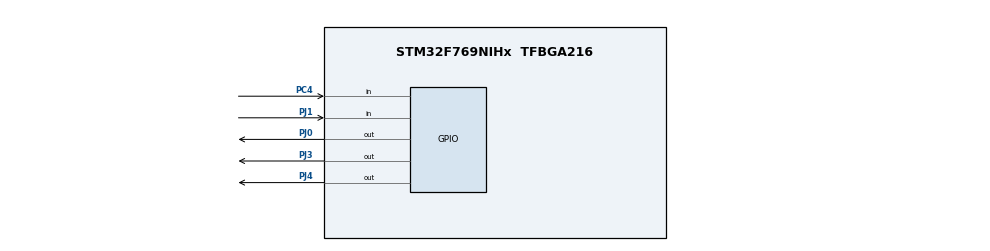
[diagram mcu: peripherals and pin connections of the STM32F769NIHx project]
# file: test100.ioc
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Mcu.Family=STM32F7
Mcu.Name=STM32F769NIHx
Mcu.Package=TFBGA216
NVIC.PriorityGroup=NVIC_PRIORITYGROUP_4
PC4.Signal=GPIO_Input
PJ0.Signal=GPIO_Output
PJ1.Signal=GPIO_Input
PJ3.Signal=GPIO_Output
PJ4.Signal=GPIO_Output
ProjectManager.HeapSize=0x200
ProjectManager.StackSize=0x400
ProjectManager.TargetToolchain=STM32CubeIDE
RCC.HSE_VALUE=25000000
RCC.HSI_VALUE=16000000
RCC.LSE_VALUE=32768
RCC.USBFreq_Value=96000000
RCC.VCOOutputFreq_Value=192000000
board=custom

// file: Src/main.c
/* USER CODE BEGIN Header */
/**
  ******************************************************************************
  * @file           : main.c
  * @brief          : Main program body
  ******************************************************************************
  * @attention
  *
  * <h2><center>&copy; Copyright (c) 2019 STMicroelectronics.
  * All rights reserved.</center></h2>
  *
  * This software component is licensed by ST under BSD 3-Clause license,
  * the "License"; You may not use this file except in compliance with the
  * License. You may obtain a copy of the License at:
  *                        opensource.org/licenses/BSD-3-Clause
  *
  ******************************************************************************
  */
/* USER CODE END Header */

#include "main.h"

void SystemClock_Config(void);
static void MX_GPIO_Init(void);

int main(void)
{

  /* MCU Configuration--------------------------------------------------------*/

  /* Reset of all peripherals, Initializes the Flash interface and the Systick. */
  HAL_Init();

  /* Configure the system clock */
  SystemClock_Config();

  /* Initialize all configured peripherals */
  MX_GPIO_Init();
  /* USER CODE BEGIN 2 */

  int count=0, oldState=GPIO_PIN_RESET;

  /* USER CODE END 2 */

  /* Infinite loop */
  while (1)
  {
	  HAL_Delay(100);
	  if(HAL_GPIO_ReadPin(GPIOJ,GPIO_PIN_1)==GPIO_PIN_SET && HAL_GPIO_ReadPin(GPIOJ,GPIO_PIN_1)!=oldState){
		  count++;
		  HAL_GPIO_WritePin(GPIOJ,GPIO_PIN_0,GPIO_PIN_RESET);
		  HAL_GPIO_WritePin(GPIOJ,GPIO_PIN_3,GPIO_PIN_RESET);
		  HAL_GPIO_WritePin(GPIOJ,GPIO_PIN_4,GPIO_PIN_RESET);
	  }
	  switch (count%3){
	  		case 0:
	  			HAL_GPIO_WritePin(GPIOJ,GPIO_PIN_0,GPIO_PIN_SET);
	  		  	break;
	  		case 1:
	  			HAL_GPIO_WritePin(GPIOJ,GPIO_PIN_3,GPIO_PIN_SET);
	  			break;
	  		case 2:
	  			HAL_GPIO_WritePin(GPIOJ,GPIO_PIN_4,GPIO_PIN_SET);
	  		  	break;
	  }
	  oldState=HAL_GPIO_ReadPin(GPIOJ,GPIO_PIN_1);

  }
}

void SystemClock_Config(void)
{
  RCC_OscInitTypeDef RCC_OscInitStruct = {0};
  RCC_ClkInitTypeDef RCC_ClkInitStruct = {0};

  /** Configure the main internal regulator output voltage
  */
  __HAL_RCC_PWR_CLK_ENABLE();
  __HAL_PWR_VOLTAGESCALING_CONFIG(PWR_REGULATOR_VOLTAGE_SCALE3);
  /** Initializes the CPU, AHB and APB busses clocks
  */
  RCC_OscInitStruct.OscillatorType = RCC_OSCILLATORTYPE_HSI;
  RCC_OscInitStruct.HSIState = RCC_HSI_ON;
  RCC_OscInitStruct.HSICalibrationValue = RCC_HSICALIBRATION_DEFAULT;
  RCC_OscInitStruct.PLL.PLLState = RCC_PLL_NONE;
  if (HAL_RCC_OscConfig(&RCC_OscInitStruct) != HAL_OK)
  {
    Error_Handler();
  }
  /** Initializes the CPU, AHB and APB busses clocks
  */
  RCC_ClkInitStruct.ClockType = RCC_CLOCKTYPE_HCLK|RCC_CLOCKTYPE_SYSCLK
                              |RCC_CLOCKTYPE_PCLK1|RCC_CLOCKTYPE_PCLK2;
  RCC_ClkInitStruct.SYSCLKSource = RCC_SYSCLKSOURCE_HSI;
  RCC_ClkInitStruct.AHBCLKDivider = RCC_SYSCLK_DIV1;
  RCC_ClkInitStruct.APB1CLKDivider = RCC_HCLK_DIV1;
  RCC_ClkInitStruct.APB2CLKDivider = RCC_HCLK_DIV1;

  if (HAL_RCC_ClockConfig(&RCC_ClkInitStruct, FLASH_LATENCY_0) != HAL_OK)
  {
    Error_Handler();
  }
}

static void MX_GPIO_Init(void)
{
  GPIO_InitTypeDef GPIO_InitStruct = {0};

  /* GPIO Ports Clock Enable */
  __HAL_RCC_GPIOJ_CLK_ENABLE();

  /*Configure GPIO pin Output Level */
  HAL_GPIO_WritePin(GPIOJ, GPIO_PIN_4|GPIO_PIN_3|GPIO_PIN_0, GPIO_PIN_RESET);

  /*Configure GPIO pins : PJ4 PJ3 PJ0 */
  GPIO_InitStruct.Pin = GPIO_PIN_4|GPIO_PIN_3|GPIO_PIN_0;
  GPIO_InitStruct.Mode = GPIO_MODE_OUTPUT_PP;
  GPIO_InitStruct.Pull = GPIO_NOPULL;
  GPIO_InitStruct.Speed = GPIO_SPEED_FREQ_LOW;
  HAL_GPIO_Init(GPIOJ, &GPIO_InitStruct);

  /*Configure GPIO pin : PJ1 */
  GPIO_InitStruct.Pin = GPIO_PIN_1;
  GPIO_InitStruct.Mode = GPIO_MODE_INPUT;
  GPIO_InitStruct.Pull = GPIO_NOPULL;
  HAL_GPIO_Init(GPIOJ, &GPIO_InitStruct);

}

void Error_Handler(void)
{
}

/************************ (C) COPYRIGHT STMicroelectronics *****END OF FILE****/
